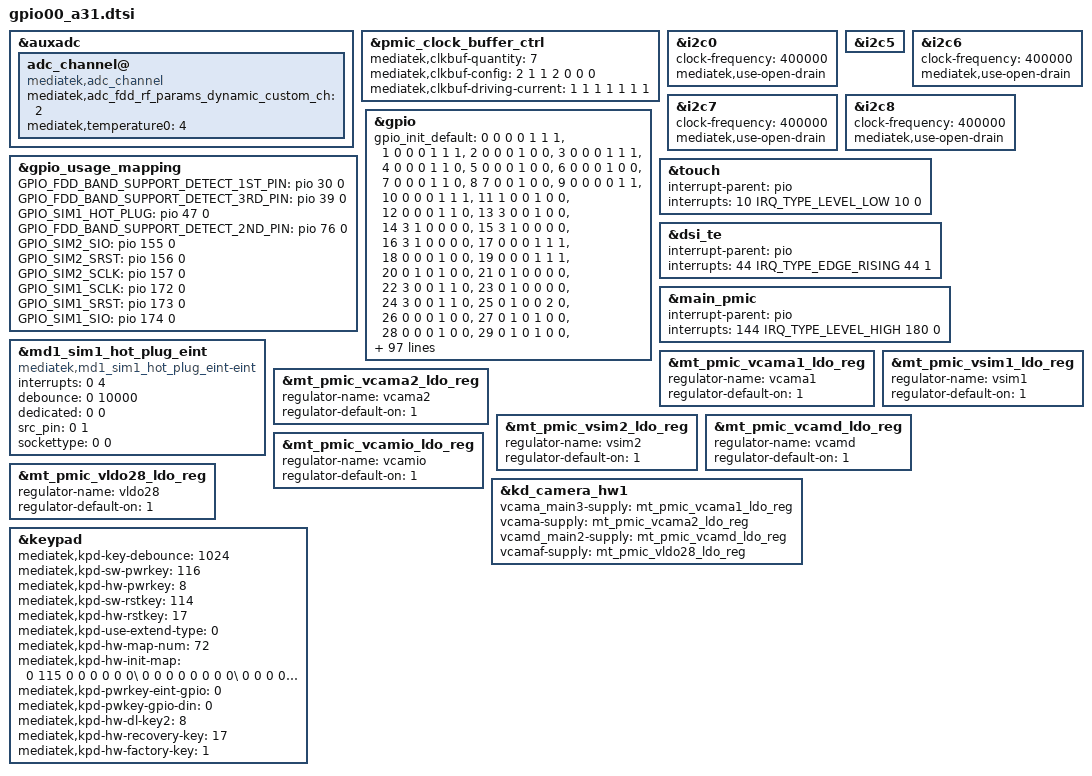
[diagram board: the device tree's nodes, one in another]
/*
 *Copyright (C) 2019 MediaTek Inc.
 *
 *This program is free software: you can redistribute it and/or modify
 *it under the terms of the GNU General Public License version 2 as
 *published by the Free Software Foundation.
 *
 *This program is distributed in the hope that it will be useful,
 *but WITHOUT ANY WARRANTY; without even the implied warranty of
 *MERCHANTABILITY or FITNESS FOR A PARTICULAR PURPOSE. See the
 *GNU General Public License for more details.
 *
 *You should have received a copy of the GNU General Public License
 *along with this program.
 *If not, see <http://www.gnu.org/licenses/>.
 */

/*
 * Generated by MTK SP DrvGen Version: 3.5.160809 for MT6768.
 * 2019-11-27 10:30:41
 * Do Not Modify The File.
 */
/*************************
 * ADC DTSI File
 *************************/

&auxadc {
	adc_channel@ {
		compatible = "mediatek,adc_channel";
		mediatek,adc_fdd_rf_params_dynamic_custom_ch = <2>;
		mediatek,temperature0 = <4>;
		status = "okay";
	};
};


/*************************
 * CLK_BUF DTSI File
 *************************/

&pmic_clock_buffer_ctrl {
	mediatek,clkbuf-quantity = <7>;
	mediatek,clkbuf-config = <2 1 1 2 0 0 0>;
	mediatek,clkbuf-driving-current = <1 1 1 1 1 1 1>;
	status = "okay";
};


/*************************
 * I2C DTSI File
 *************************/

&i2c0 {
	#address-cells = <1>;
	#size-cells = <0>;
	clock-frequency = <400000>;
	mediatek,use-open-drain;
};

&i2c5 {
	#address-cells = <1>;
	#size-cells = <0>;
/*	clock-frequency = <3400000>; */
/*	mediatek,use-push-pull; */
};

&i2c6 {
	#address-cells = <1>;
	#size-cells = <0>;
	clock-frequency = <400000>;
	mediatek,use-open-drain;
};

&i2c7 {
	#address-cells = <1>;
	#size-cells = <0>;
	clock-frequency = <400000>;
	mediatek,use-open-drain;
};

&i2c8 {
	#address-cells = <1>;
	#size-cells = <0>;
	clock-frequency = <400000>;
	mediatek,use-open-drain;
};



/*************************
 * GPIO DTSI File
 *************************/

&gpio_usage_mapping {
	GPIO_FDD_BAND_SUPPORT_DETECT_1ST_PIN = <&pio 30 0>;
	GPIO_FDD_BAND_SUPPORT_DETECT_3RD_PIN = <&pio 39 0>;
	GPIO_SIM1_HOT_PLUG = <&pio 47 0>;
	GPIO_FDD_BAND_SUPPORT_DETECT_2ND_PIN = <&pio 76 0>;
	GPIO_SIM2_SIO = <&pio 155 0>;
	GPIO_SIM2_SRST = <&pio 156 0>;
	GPIO_SIM2_SCLK = <&pio 157 0>;
	GPIO_SIM1_SCLK = <&pio 172 0>;
	GPIO_SIM1_SRST = <&pio 173 0>;
	GPIO_SIM1_SIO = <&pio 174 0>;
};

&gpio{
	gpio_init_default = <0 0 0 0 1 1 1>,
		<1 0 0 0 1 1 1>,
		<2 0 0 0 1 0 0>,
		<3 0 0 0 1 1 1>,
		<4 0 0 0 1 1 0>,
		<5 0 0 0 1 0 0>,
		<6 0 0 0 1 0 0>,	/* BTP_IRQ */
		<7 0 0 0 1 1 0>,
		<8 7 0 0 1 0 0>,
		<9 0 0 0 0 1 1>,
		<10 0 0 0 1 1 1>,
		<11 1 0 0 1 0 0>,
		<12 0 0 0 1 1 0>,
		<13 3 0 0 1 0 0>,
		<14 3 1 0 0 0 0>,
		<15 3 1 0 0 0 0>,
		<16 3 1 0 0 0 0>,
		<17 0 0 0 1 1 1>,
		<18 0 0 0 1 0 0>,	/* HALL_INT - NC */
		<19 0 0 0 1 1 1>,
		<20 0 1 0 1 0 0>,	/* FCAM_RST_N */
		<21 0 1 0 0 0 0>,
		<22 3 0 0 1 1 0>,
		<23 0 1 0 0 0 0>,
		<24 3 0 0 1 1 0>,
		<25 0 1 0 0 2 0>,	/* LCD_EN_1P8 */
		<26 0 0 0 1 0 0>,
		<27 0 1 0 1 0 0>,	/* RCAM3_RST_N */
		<28 0 0 0 1 0 0>,	/* FG_ERR */
		<29 0 1 0 1 0 0>,	/* RCAM4_DVDD_1P2_EN */
		<30 0 0 0 1 0 0>,
		<31 0 0 0 0 0 0>,
		<32 7 1 0 0 0 0>,
		<33 7 0 0 1 0 0>,
		<34 7 0 0 1 0 0>,
		<35 7 0 0 1 0 0>,
		<36 2 1 0 0 0 0>,
		<37 2 1 0 0 0 0>,
		<38 2 1 0 0 0 0>,
		<39 0 0 0 1 0 0>,
		<40 2 0 0 1 0 0>,
		<41 0 0 0 1 0 1>,
		<42 0 0 0 1 0 1>,
		<43 0 0 0 1 1 0>,
		<44 1 0 0 1 0 0>,	/* DISP_TE */
		<45 0 1 0 0 2 0>,	/* OCTA_RST_N */
		<46 0 0 0 1 0 0>,	/* NC */
		<47 1 0 0 1 1 0>,
		<48 1 0 0 1 1 1>,
		<49 1 0 0 1 1 1>,
		<50 1 0 0 1 1 1>,
		<51 1 0 0 1 1 1>,
		<52 0 0 0 1 0 0>,
		<53 0 0 0 1 0 0>,
		<54 0 0 0 1 0 0>,	/* PCD_INT */
		<55 1 0 0 1 0 0>,
		<56 1 0 0 1 0 0>,
		<57 1 0 0 1 0 0>,
		<58 0 0 0 1 0 0>,	/* NC */
		<59 1 0 0 1 0 0>,
		<60 1 0 0 1 0 0>,
		<61 1 0 0 1 0 0>,
		<62 1 0 0 1 0 0>,
		<63 1 0 0 1 0 0>,
		<64 1 0 0 1 0 0>,
		<65 1 0 0 1 0 0>,
		<66 1 0 0 1 0 0>,
		<67 1 0 0 1 0 0>,
		<68 1 0 0 1 0 0>,
		<69 0 0 0 0 0 0>,
		<70 1 0 0 1 0 0>,
		<71 1 0 0 1 0 0>,
		<72 1 0 0 1 0 0>,
		<73 1 0 0 1 0 0>,
		<74 1 0 0 1 0 0>,
		<75 1 0 0 1 0 0>,
		<76 0 0 0 1 0 0>,
		<77 1 0 0 1 0 0>,
		<78 0 0 0 1 0 0>,
		<79 0 0 0 0 0 0>,
		<80 0 0 0 1 0 0>,
		<81 1 0 0 1 1 1>,
		<82 1 0 0 1 1 1>,
		<83 1 0 0 1 1 1>,
		<84 1 0 0 1 1 1>,
		<85 2 0 0 1 0 0>,
		<86 2 1 0 0 0 0>,
		<87 2 1 0 0 0 0>,
		<88 2 1 0 0 0 0>,
		<89 1 0 0 1 1 1>,
		<90 1 0 0 1 1 1>,
		<91 0 1 0 1 0 0>,	/* MIPI_SEL */
		<92 0 0 0 0 2 0>,	/* LCD_DET for FD */
		<93 1 0 0 1 1 0>,
		<94 1 0 0 1 1 0>,
		<95 1 0 0 1 1 0>,
		<96 1 1 0 0 0 0>,
		<97 0 0 0 1 0 0>,	/* NC */
		<98 0 1 0 1 0 0>,	/* RCAM4_AVDD_2P8_EN */
		<99 1 1 0 0 0 0>,
		<100 1 1 0 0 0 0>,
		<101 0 1 0 1 0 0>,	/* RCAM2_RST_N */
		<102 0 1 0 1 0 0>,	/* RCAM1_RST_N */
		<103 1 0 0 1 1 1>,
		<104 1 0 0 1 1 1>,
		<105 1 0 0 1 1 1>,
		<106 1 0 0 1 1 1>,
		<107 0 0 0 1 0 0>,	/* NC */
		<108 1 1 0 0 0 0>,
		<109 0 1 0 1 0 0>,	/* RCAM4_RST_N */
		<110 0 0 0 1 0 0>,	/* NC */
		<111 1 1 0 0 0 0>,
		<112 0 0 0 1 0 0>,	/* NC */
		<113 0 1 0 1 0 0>,	/* CONN_TOP_CLK */
		<114 1 1 0 1 0 1>,	/* CONN_TOP_DATA */
		<115 0 1 0 1 0 0>,	/* CONN_BT_CLK */
		<116 1 1 0 1 0 1>,	/* CONN_BT_DATA */
		<117 0 0 0 1 0 0>,
		<118 0 0 0 1 0 0>,
		<119 0 0 0 1 0 0>,
		<120 0 1 0 1 0 0>,	/* CONN_WB_PTA */
		<121 0 1 0 1 0 0>,	/* CONN_HRST_B */
		<122 1 0 0 1 1 1>,
		<123 1 0 0 1 1 1>,
		<124 1 1 0 0 0 1>,
		<125 1 0 0 1 1 1>,
		<126 1 0 0 1 1 1>,
		<127 1 0 0 1 1 1>,
		<128 1 0 0 1 1 1>,
		<129 1 0 0 1 1 1>,
		<130 1 0 0 1 1 1>,
		<131 1 1 0 0 0 1>,
		<132 1 0 0 1 1 1>,
		<133 1 1 0 0 0 1>,
		<134 1 0 0 1 0 1>,
		<135 1 1 0 0 0 0>,
		<136 1 1 0 0 0 0>,
		<137 1 1 0 0 0 0>,
		<138 1 1 0 0 0 0>,
		<139 1 1 0 0 0 0>,
		<140 1 0 0 1 0 0>,
		<141 1 0 0 1 0 0>,
		<142 1 0 0 1 0 0>,
		<143 1 0 0 1 0 0>,
		<144 1 0 0 1 0 0>,
		<145 1 1 0 0 0 0>,
		<146 1 1 0 0 0 0>,
		<147 1 1 0 0 0 0>,
		<148 1 1 0 0 0 0>,
		<149 1 1 0 0 0 0>,
		<150 0 0 0 1 0 0>,
		<151 0 0 0 1 0 0>,
		<152 0 1 1 1 0 0>,
		<153 0 1 0 0 2 0>,	/* LCD_EN_3P0 */
		<154 1 1 0 0 0 0>,
		<155 1 0 0 1 1 0>,
		<156 1 1 0 0 0 0>,
		<157 1 1 0 0 0 0>,
		<158 0 0 0 1 0 0>,
		<159 0 1 0 0 0 0>,
		<160 0 0 0 1 0 0>,	/* NC */
		<161 1 0 0 1 1 1>,
		<162 1 0 0 1 1 1>,
		<163 1 0 0 1 1 1>,
		<164 1 0 0 1 1 1>,
		<165 0 1 0 1 0 0>,
		<166 0 1 0 1 0 0>,
		<167 1 0 0 1 0 0>,
		<168 1 0 0 1 0 0>,
		<169 0 0 0 0 2 0>,	/* CON_DET */
		<170 1 0 0 1 1 1>,
		<171 1 1 0 0 0 1>,
		<172 1 1 0 0 0 0>,
		<173 1 1 0 0 0 0>,
		<174 1 0 0 1 1 0>,
		<175 2 0 1 1 1 1>,
		<176 2 0 1 1 1 1>,
		<177 0 0 0 1 0 0>,
		<178 0 1 1 0 0 0>,
		<179 0 0 0 1 0 0>,	/* EL_ON1_DET */
		<180 0 0 0 1 0 0>,
		<181 0 0 0 1 0 0>,
		<182 0 0 0 1 0 0>,
		<183 0 0 0 1 0 0>,
		<184 0 0 0 1 0 0>,
		<185 0 0 0 1 0 0>,
		<186 0 0 0 1 0 0>;
};

&gpio{
	gpio_init_default_samsung = 
		<6 0 0 0 1 0 0>,	/* BTP_IRQ */
		<18 0 0 0 1 0 0>,	/* HALL_INT - NC */
		<20 0 1 0 1 0 0>,	/* FCAM_RST_N */
		<25 0 1 0 0 2 0>,	/* LCD_EN_1P8 */
		<27 0 1 0 1 0 0>,	/* RCAM3_RST_N */
		<28 0 0 0 1 0 0>,	/* FG_ERR */
		<29 0 1 0 1 0 0>,	/* RCAM4_DVDD_1P2_EN */
		<30 0 0 0 1 0 0>,
		<39 0 0 0 1 0 0>,
		<46 0 0 0 1 0 0>,	/* NC */
		<78 0 0 0 1 0 0>,
		<44 1 0 0 1 0 0>,	/* DISP_TE */
		<45 0 1 0 0 2 0>,	/* OCTA_RST_N */
		<54 0 0 0 1 0 0>,	/* PCD_INT */
		<58 0 0 0 1 0 0>,	/* NC */
		<91 0 1 0 1 0 0>,	/* MIPI_SEL */
		<92 0 0 0 0 2 0>,	/* LCD_DET for FD */
		<97 0 0 0 1 0 0>,	/* NC */
		<98 0 1 0 1 0 0>,	/* RCAM4_AVDD_2P8_EN */
		<101 0 1 0 1 0 0>,	/* RCAM2_RST_N */
		<102 0 1 0 1 0 0>,	/* RCAM1_RST_N */
		<107 0 0 0 1 0 0>,	/* NC */
		<109 0 1 0 1 0 0>,	/* RCAM4_RST_N */
		<110 0 0 0 1 0 0>,	/* NC */
		<112 0 0 0 1 0 0>,	/* NC */
		<113 0 1 0 1 0 0>,	/* CONN_TOP_CLK */
		<114 1 1 0 1 0 1>,	/* CONN_TOP_DATA */
		<115 0 1 0 1 0 0>,	/* CONN_BT_CLK */
		<116 1 1 0 1 0 1>,	/* CONN_BT_DATA */
		<120 0 1 0 1 0 0>,	/* CONN_WB_PTA */
		<121 0 1 0 1 0 0>,	/* CONN_HRST_B */
		<153 0 1 0 0 2 0>,	/* LCD_EN_3P0 */
		<160 0 0 0 1 0 0>,	/* NC */
		<169 0 0 0 0 2 0>,	/* CON_DET */
		<179 0 0 0 1 0 0>;	/* EL_ON1_DET */
};

/*************************
 * EINT DTSI File
 *************************/

#include <dt-bindings/interrupt-controller/irq.h>
#include <dt-bindings/interrupt-controller/arm-gic.h>

&touch {
	interrupt-parent = <&pio>;
	interrupts = <10 IRQ_TYPE_LEVEL_LOW 10 0>;
	status = "okay";
};

&dsi_te {
	interrupt-parent = <&pio>;
	interrupts = <44 IRQ_TYPE_EDGE_RISING 44 1>;
	status = "okay";
};

&main_pmic {
	interrupt-parent = <&pio>;
	interrupts = <144 IRQ_TYPE_LEVEL_HIGH 180 0>;
	status = "okay";
};



/*************************
 * MD1_EINT DTSI File
 *************************/

&md1_sim1_hot_plug_eint {
	compatible = "mediatek,md1_sim1_hot_plug_eint-eint";
	interrupts = <0 4>;
	debounce = <0 10000>;
	dedicated = <0 0>;
	src_pin = <0 1>;
	sockettype = <0 0>;
	status = "okay";
};



/*************************
 * PMIC DTSI File
 *************************/

&mt_pmic_vcama1_ldo_reg {
	regulator-name = "vcama1";
	regulator-default-on = <1>; /* 0:skip, 1: off, 2:on */
	status = "okay";
};
&mt_pmic_vcama2_ldo_reg {
	regulator-name = "vcama2";
	regulator-default-on = <1>; /* 0:skip, 1: off, 2:on */
	status = "okay";
};
&mt_pmic_vsim1_ldo_reg {
	regulator-name = "vsim1";
	regulator-default-on = <1>; /* 0:skip, 1: off, 2:on */
	status = "okay";
};
&mt_pmic_vsim2_ldo_reg {
	regulator-name = "vsim2";
	regulator-default-on = <1>; /* 0:skip, 1: off, 2:on */
	status = "okay";
};
&mt_pmic_vcamd_ldo_reg {
	regulator-name = "vcamd";
	regulator-default-on = <1>; /* 0:skip, 1: off, 2:on */
	status = "okay";
};
&mt_pmic_vcamio_ldo_reg {
	regulator-name = "vcamio";
	regulator-default-on = <1>; /* 0:skip, 1: off, 2:on */
	status = "okay";
};
&mt_pmic_vldo28_ldo_reg {
	regulator-name = "vldo28";
	regulator-default-on = <1>; /* 0:skip, 1: off, 2:on */
	status = "okay";
};

&kd_camera_hw1 {
	vcama_main3-supply = <&mt_pmic_vcama1_ldo_reg>;
	vcama-supply = <&mt_pmic_vcama2_ldo_reg>;
	vcamd_main2-supply = <&mt_pmic_vcamd_ldo_reg>;
	vcamaf-supply = <&mt_pmic_vldo28_ldo_reg>;
	status = "okay";
};

&touch {
	status = "okay";
};


/*************************
 * POWER DTSI File
 *************************/



/*************************
 * KPD DTSI File
 *************************/

&keypad {
	mediatek,kpd-key-debounce = <1024>;
	mediatek,kpd-sw-pwrkey = <116>;
	mediatek,kpd-hw-pwrkey = <8>;
	mediatek,kpd-sw-rstkey  = <114>;
	mediatek,kpd-hw-rstkey = <17>;
	mediatek,kpd-use-extend-type = <0>;
	/*HW Keycode [0~71] -> Linux Keycode*/
	mediatek,kpd-hw-map-num = <72>;
	mediatek,kpd-hw-init-map = <0 115 0 0 0 0 0 0\
		0 0 0 0 0 0 0 0\
		0 0 0 0 0 0 0 0\
		0 0 0 0 0 0 0 0\
		0 0 0 0 0 0 0 0\
		0 0 0 0 0 0 0 0\
		0 0 0 0 0 0 0 0\
		0 0 0 0 0 0 0 0\
		0 0 0 0 0 0 0 0>;
	mediatek,kpd-pwrkey-eint-gpio = <0>;
	mediatek,kpd-pwkey-gpio-din  = <0>;
	mediatek,kpd-hw-dl-key2 = <8>;
	mediatek,kpd-hw-recovery-key = <17>;
	mediatek,kpd-hw-factory-key = <1>;
	status = "okay";
};


